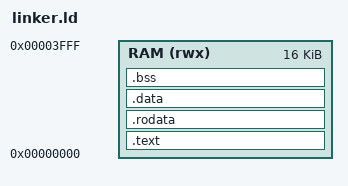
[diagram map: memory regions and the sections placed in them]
OUTPUT_ARCH(riscv)
ENTRY(_start)

MEMORY {
    RAM (rwx) : ORIGIN = 0x00000000, LENGTH = 16K
}

SECTIONS {
    .text : {
        *(.text.init)
        *(.text .text.*)
    } > RAM

    .rodata : {
        *(.rodata .rodata.*)
    } > RAM

    .data : {
        . = ALIGN(4);
        *(.data .data.*)
        *(.sdata .sdata.*)
    } > RAM

    .bss : {
        . = ALIGN(4);
        __bss_start = .;
        *(.bss .bss.*)
        *(.sbss .sbss.*)
        __bss_end = .;
    } > RAM

    __stack_top = ORIGIN(RAM) + LENGTH(RAM);
}
